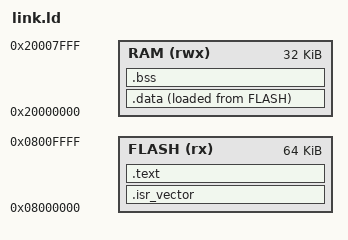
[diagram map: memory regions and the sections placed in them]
/* Minimal STM32G0 link script: flash at 0x08000000, 32 KiB SRAM at 0x20000000. */
MEMORY
{
  FLASH (rx) : ORIGIN = 0x08000000, LENGTH = 64K
  RAM  (rwx) : ORIGIN = 0x20000000, LENGTH = 32K
}

_estack = ORIGIN(RAM) + LENGTH(RAM);

SECTIONS
{
  .isr_vector : { KEEP(*(.isr_vector)) } > FLASH
  .text   : { *(.text*) *(.rodata*) } > FLASH
  .data   : { *(.data*) } > RAM AT > FLASH
  .bss    : { *(.bss*) *(COMMON) } > RAM
  /DISCARD/ : { *(.ARM.exidx*) *(.comment) }
}
